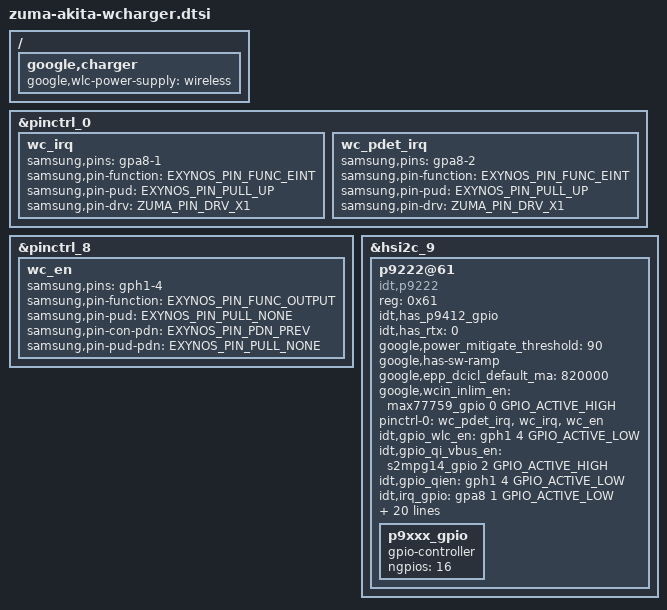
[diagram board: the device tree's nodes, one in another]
// SPDX-License-Identifier: GPL-2.0-only
/*
 * Wireless Charger device tree entries.
 *
 * Copyright 2022 Google LLC
 */

#include <arm64/exynos/exynos-pinctrl.h>
#include <dt-bindings/interrupt-controller/irq.h>

/ {
	fragment@wlc {
		target-path = "/";
		__overlay__ {
			google,charger {
				google,wlc-power-supply = "wireless";
			};
		};
	};
};

&pinctrl_0 {
	/* XIENT_23 P9412 Wireless Charger Interrupt */
	wc_irq: wc_irq {
		samsung,pins = "gpa8-1"; /* QI_INT_ODL */
		samsung,pin-function = <EXYNOS_PIN_FUNC_EINT>;
		samsung,pin-pud = <EXYNOS_PIN_PULL_UP>;
		samsung,pin-drv = <ZUMA_PIN_DRV_X1>;
	};
	wc_pdet_irq: wc_pdet_irq {
		samsung,pins = "gpa8-2"; /* QI_INT_R */
		samsung,pin-function = <EXYNOS_PIN_FUNC_EINT>;
		samsung,pin-pud = <EXYNOS_PIN_PULL_UP>;
		samsung,pin-drv = <ZUMA_PIN_DRV_X1>;
	};
};

&pinctrl_8 {
	/* XHSI1_GPIO6 P9412 Wireless Charger Enable */
	wc_en: wc_en {
		samsung,pins = "gph1-4"; /* QI_EN_L */
		samsung,pin-function = <EXYNOS_PIN_FUNC_OUTPUT>;
		samsung,pin-pud = <EXYNOS_PIN_PULL_NONE>;
		samsung,pin-con-pdn = <EXYNOS_PIN_PDN_PREV>;
		samsung,pin-pud-pdn = <EXYNOS_PIN_PULL_NONE>;
	};
};

&hsi2c_9 {
	#address-cells = <1>;
	#size-cells = <0>;

	p9222@61 {
		compatible = "idt,p9222";
		reg = <0x61>;
		status = "ok";

		/* Support p9412 GPIO */
		idt,has_p9412_gpio;

		idt,has_rtx = <0>;

		google,power_mitigate_threshold = <90>;
		google,has-sw-ramp;
		google,epp_dcicl_default_ma = <820000>;
		google,wcin_inlim_en = <&max77759_gpio 0 GPIO_ACTIVE_HIGH>;

		pinctrl-names = "default";
		pinctrl-0 = <&wc_pdet_irq &wc_irq &wc_en>;

		idt,gpio_wlc_en = <&gph1 4 GPIO_ACTIVE_LOW>; /* QI_EN_L */
		idt,gpio_qi_vbus_en = <&s2mpg14_gpio 2 GPIO_ACTIVE_HIGH>; /* QI_USB_VBUS_EN */
		idt,gpio_qien = <&gph1 4 GPIO_ACTIVE_LOW>; /* QI_EN_L */
		idt,irq_gpio = <&gpa8 1 GPIO_ACTIVE_LOW>; /* QI_INT_ODL */
		idt,gpio_slct = <&s2mpg14_gpio 0 GPIO_ACTIVE_HIGH>; /* QI_BPP_EPP_SLCT */
		idt,gpio_slct_value = <1>;
		idt,irq_det_gpio = <&gpa8 2 GPIO_ACTIVE_LOW>;

		idt,max_vout_mv = <10000>;  /* max voltage in mV */

		google,q_value = <54>;
		google,tx1801_q = <10>;
		google,rf_value = <88>;
		google,lowest-freq-limit-khz = <121>;
		google,bpp_iop_vout_mv = <5500>;
		google,epp_iop_vout_mv = <9500>;
		google,iop_fod_mfg = [011B 00B3];
		fod = [8D 34 82 32 95 18 8D 2A A4 F7 B1 CA 00 00 00 29];
		fod_epp = [8B 4A 7C 59 93 13 8F 28 95 06 9F C8 00 00 00 29];
		fod_epp_iop = [8b 4a 7c 59 93 20 8f 28 95 1a 9f c8 00 00 00 29];
		fod_gpp = [8b 4a 7c 59 93 27 8f 28 95 32 ab c8 00 00 00 29];

		google,wlc_qispec = <0x1300>;

		p9xxx_gpio: p9xxx_gpio {
			gpio-controller;
			#gpio-cells = <2>;
			ngpios = <16>;
		};
	};
};
